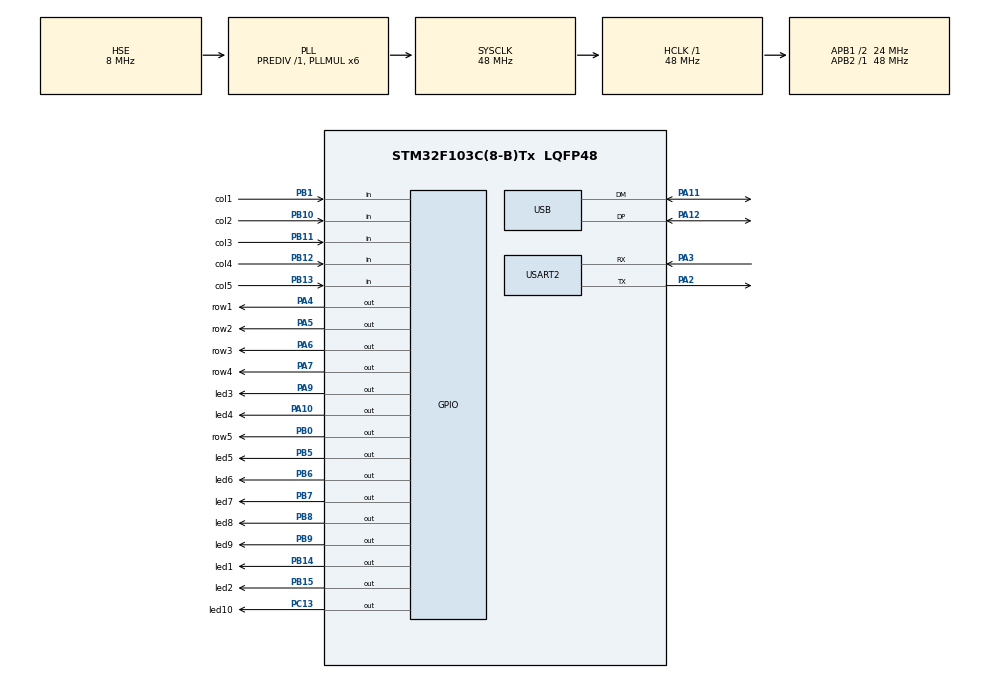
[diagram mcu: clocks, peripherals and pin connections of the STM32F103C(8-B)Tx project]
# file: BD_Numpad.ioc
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Mcu.Family=STM32F1
Mcu.Name=STM32F103C(8-B)Tx
Mcu.Package=LQFP48
NVIC.PriorityGroup=NVIC_PRIORITYGROUP_4
NVIC.USB_LP_CAN1_RX0_IRQn=true\:0\:0\:false\:false\:true\:false\:true\:true
PA10.GPIO_Label=led4
PA10.GPIO_PuPd=GPIO_PULLDOWN
PA10.GPIO_Speed=GPIO_SPEED_FREQ_HIGH
PA10.Signal=GPIO_Output
PA11.Mode=Device
PA11.Signal=USB_DM
PA12.Mode=Device
PA12.Signal=USB_DP
PA13.Mode=Serial_Wire
PA13.Signal=SYS_JTMS-SWDIO
PA14.Mode=Serial_Wire
PA14.Signal=SYS_JTCK-SWCLK
PA2.Mode=Asynchronous
PA2.Signal=USART2_TX
PA3.Mode=Asynchronous
PA3.Signal=USART2_RX
PA4.GPIO_Label=row1
PA4.GPIO_PuPd=GPIO_PULLDOWN
PA4.GPIO_Speed=GPIO_SPEED_FREQ_HIGH
PA4.Signal=GPIO_Output
PA5.GPIO_Label=row2
PA5.GPIO_PuPd=GPIO_PULLDOWN
PA5.GPIO_Speed=GPIO_SPEED_FREQ_HIGH
PA5.Signal=GPIO_Output
PA6.GPIO_Label=row3
PA6.GPIO_PuPd=GPIO_PULLDOWN
PA6.GPIO_Speed=GPIO_SPEED_FREQ_HIGH
PA6.Signal=GPIO_Output
PA7.GPIO_Label=row4
PA7.GPIO_PuPd=GPIO_PULLDOWN
PA7.GPIO_Speed=GPIO_SPEED_FREQ_HIGH
PA7.Signal=GPIO_Output
PA9.GPIO_Label=led3
PA9.GPIO_PuPd=GPIO_PULLDOWN
PA9.GPIO_Speed=GPIO_SPEED_FREQ_HIGH
PA9.Signal=GPIO_Output
PB0.GPIO_Label=row5
PB0.GPIO_PuPd=GPIO_PULLDOWN
PB0.GPIO_Speed=GPIO_SPEED_FREQ_HIGH
PB0.Signal=GPIO_Output
PB1.GPIO_Label=col1
PB1.GPIO_PuPd=GPIO_PULLDOWN
PB1.Signal=GPIO_Input
PB10.GPIO_Label=col2
PB10.GPIO_PuPd=GPIO_PULLDOWN
PB10.Signal=GPIO_Input
PB11.GPIO_Label=col3
PB11.GPIO_PuPd=GPIO_PULLDOWN
PB11.Signal=GPIO_Input
PB12.GPIO_Label=col4
PB12.GPIO_PuPd=GPIO_PULLDOWN
PB12.Signal=GPIO_Input
PB13.GPIO_Label=col5
PB13.GPIO_PuPd=GPIO_PULLDOWN
PB13.Signal=GPIO_Input
PB14.GPIO_Label=led1
PB14.GPIO_PuPd=GPIO_PULLDOWN
PB14.GPIO_Speed=GPIO_SPEED_FREQ_HIGH
PB14.Signal=GPIO_Output
PB15.GPIO_Label=led2
PB15.GPIO_PuPd=GPIO_PULLDOWN
PB15.GPIO_Speed=GPIO_SPEED_FREQ_HIGH
PB15.Signal=GPIO_Output
PB5.GPIO_Label=led5
PB5.GPIO_PuPd=GPIO_PULLDOWN
PB5.GPIO_Speed=GPIO_SPEED_FREQ_HIGH
PB5.Signal=GPIO_Output
PB6.GPIO_Label=led6
PB6.GPIO_PuPd=GPIO_PULLDOWN
PB6.GPIO_Speed=GPIO_SPEED_FREQ_HIGH
PB6.Signal=GPIO_Output
PB7.GPIO_Label=led7
PB7.GPIO_PuPd=GPIO_PULLDOWN
PB7.GPIO_Speed=GPIO_SPEED_FREQ_HIGH
PB7.Signal=GPIO_Output
PB8.GPIO_Label=led8
PB8.GPIO_PuPd=GPIO_PULLDOWN
PB8.GPIO_Speed=GPIO_SPEED_FREQ_HIGH
PB8.Signal=GPIO_Output
PB9.GPIO_Label=led9
PB9.GPIO_PuPd=GPIO_PULLDOWN
PB9.GPIO_Speed=GPIO_SPEED_FREQ_HIGH
PB9.Signal=GPIO_Output
PC13-TAMPER-RTC.GPIO_Label=led10
PC13-TAMPER-RTC.GPIO_PuPd=GPIO_PULLDOWN
PC13-TAMPER-RTC.GPIO_Speed=GPIO_SPEED_FREQ_HIGH
PC13-TAMPER-RTC.Signal=GPIO_Output
PD0-OSC_IN.Mode=HSE-External-Oscillator
PD0-OSC_IN.Signal=RCC_OSC_IN
PD1-OSC_OUT.Mode=HSE-External-Oscillator
PD1-OSC_OUT.Signal=RCC_OSC_OUT
ProjectManager.HeapSize=0x200
ProjectManager.StackSize=0x400
ProjectManager.TargetToolchain=STM32CubeIDE
RCC.AHBFreq_Value=48000000
RCC.APB1CLKDivider=RCC_HCLK_DIV2
RCC.APB1Freq_Value=24000000
RCC.APB1TimFreq_Value=48000000
RCC.APB2Freq_Value=48000000
RCC.APB2TimFreq_Value=48000000
RCC.HCLKFreq_Value=48000000
RCC.PLLMUL=RCC_PLL_MUL6
RCC.SYSCLKFreq_VALUE=48000000
RCC.SYSCLKSource=RCC_SYSCLKSOURCE_PLLCLK
RCC.USBFreq_Value=48000000
USART2.VirtualMode=VM_ASYNC
USB_DEVICE.CLASS_NAME_FS=HID
USB_DEVICE.PRODUCT_STRING_HID_FS=\ BD Numpad
USB_DEVICE.VirtualMode=Hid
USB_DEVICE.VirtualModeFS=Hid_FS
VP_USB_DEVICE_VS_USB_DEVICE_HID_FS.Mode=HID_FS
board=custom

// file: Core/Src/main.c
/* USER CODE BEGIN Header */
/**
  ******************************************************************************
  * @file           : main.c
  * @brief          : Main program body
  ******************************************************************************
  * @attention
  *
  * Copyright (c) 2023 STMicroelectronics.
  * All rights reserved.
  *
  * This software is licensed under terms that can be found in the LICENSE file
  * in the root directory of this software component.
  * If no LICENSE file comes with this software, it is provided AS-IS.
  *
  ******************************************************************************
  */
/* USER CODE END Header */
#include "main.h"
#include "usb_device.h"

/* USER CODE BEGIN Includes */
#include "usbd_hid.h"
#include "HIDKeyFunctions.h"
/* USER CODE END Includes */

UART_HandleTypeDef huart2;

void SystemClock_Config(void);
static void MX_GPIO_Init(void);
static void MX_USART2_UART_Init(void);

/* USER CODE BEGIN 0 */
//extern USBD_HandleTypeDef hUsbDeviceFS;
//https://youtu.be/tj1_hsQ5PR0?t=337   burda kaldin pdf indirdin
/*typedef struct {
	uint8_t MODIFIER;
	uint8_t RESERVED;
	uint8_t KEYCODE1;
	uint8_t KEYCODE2;
	uint8_t KEYCODE3;
	uint8_t KEYCODE4;
	uint8_t KEYCODE5;
	uint8_t KEYCODE6;
} keyboardHID;

keyboardHID keyboardhid = {0,0,0,0,0,0,0,0};
*/
/* USER CODE END 0 */

int main(void)
{

  /* MCU Configuration--------------------------------------------------------*/

  /* Reset of all peripherals, Initializes the Flash interface and the Systick. */
  HAL_Init();

  /* Configure the system clock */
  SystemClock_Config();

  /* Initialize all configured peripherals */
  MX_GPIO_Init();
  MX_USART2_UART_Init();
  MX_USB_DEVICE_Init();
  /* USER CODE BEGIN 2 */
  //turn on all leds.
  HAL_GPIO_WritePin(led1_GPIO_Port, led1_Pin, GPIO_PIN_SET);
  HAL_GPIO_WritePin(led2_GPIO_Port, led2_Pin, GPIO_PIN_SET);
  HAL_GPIO_WritePin(led3_GPIO_Port, led3_Pin, GPIO_PIN_SET);
  HAL_GPIO_WritePin(led4_GPIO_Port, led4_Pin, GPIO_PIN_SET);
  HAL_GPIO_WritePin(led5_GPIO_Port, led5_Pin, GPIO_PIN_SET);
  HAL_GPIO_WritePin(led6_GPIO_Port, le6_Pin, GPIO_PIN_RESET);
  HAL_GPIO_WritePin(led7_GPIO_Port, led7_Pin, GPIO_PIN_RESET);
  HAL_GPIO_WritePin(led8_GPIO_Port, led8_Pin, GPIO_PIN_RESET);
  HAL_GPIO_WritePin(led9_GPIO_Port, led9_Pin, GPIO_PIN_RESET);
  HAL_GPIO_WritePin(led10_GPIO_Port, led10_Pin, GPIO_PIN_RESET);

  /* USER CODE END 2 */

  /* Infinite loop */
  while (1)
  {

    /* USER CODE BEGIN 3 */
	  /*
	  keyboardhid.KEYCODE1 = 0x1e; //send '1'
	  USBD_HID_SendReport(&hUsbDeviceFS, &keyboardhid, sizeof(keyboardhid));

	  HAL_Delay(50);

	  keyboardhid.KEYCODE1 = 0x00; //release key
	  USBD_HID_SendReport(&hUsbDeviceFS, &keyboardhid, sizeof(keyboardhid));
	   */

	  //HAL_Delay(10000);
	  //https://youtu.be/tj1_hsQ5PR0?t=537

	  readAllPins();
	  HAL_Delay(10);

  }
  /* USER CODE END 3 */
}

void SystemClock_Config(void)
{
  RCC_OscInitTypeDef RCC_OscInitStruct = {0};
  RCC_ClkInitTypeDef RCC_ClkInitStruct = {0};
  RCC_PeriphCLKInitTypeDef PeriphClkInit = {0};

  /** Initializes the RCC Oscillators according to the specified parameters
  * in the RCC_OscInitTypeDef structure.
  */
  RCC_OscInitStruct.OscillatorType = RCC_OSCILLATORTYPE_HSE;
  RCC_OscInitStruct.HSEState = RCC_HSE_ON;
  RCC_OscInitStruct.HSEPredivValue = RCC_HSE_PREDIV_DIV1;
  RCC_OscInitStruct.HSIState = RCC_HSI_ON;
  RCC_OscInitStruct.PLL.PLLState = RCC_PLL_ON;
  RCC_OscInitStruct.PLL.PLLSource = RCC_PLLSOURCE_HSE;
  RCC_OscInitStruct.PLL.PLLMUL = RCC_PLL_MUL6;
  if (HAL_RCC_OscConfig(&RCC_OscInitStruct) != HAL_OK)
  {
    Error_Handler();
  }

  /** Initializes the CPU, AHB and APB buses clocks
  */
  RCC_ClkInitStruct.ClockType = RCC_CLOCKTYPE_HCLK|RCC_CLOCKTYPE_SYSCLK
                              |RCC_CLOCKTYPE_PCLK1|RCC_CLOCKTYPE_PCLK2;
  RCC_ClkInitStruct.SYSCLKSource = RCC_SYSCLKSOURCE_PLLCLK;
  RCC_ClkInitStruct.AHBCLKDivider = RCC_SYSCLK_DIV1;
  RCC_ClkInitStruct.APB1CLKDivider = RCC_HCLK_DIV2;
  RCC_ClkInitStruct.APB2CLKDivider = RCC_HCLK_DIV1;

  if (HAL_RCC_ClockConfig(&RCC_ClkInitStruct, FLASH_LATENCY_1) != HAL_OK)
  {
    Error_Handler();
  }
  PeriphClkInit.PeriphClockSelection = RCC_PERIPHCLK_USB;
  PeriphClkInit.UsbClockSelection = RCC_USBCLKSOURCE_PLL;
  if (HAL_RCCEx_PeriphCLKConfig(&PeriphClkInit) != HAL_OK)
  {
    Error_Handler();
  }
}

static void MX_USART2_UART_Init(void)
{

  huart2.Instance = USART2;
  huart2.Init.BaudRate = 115200;
  huart2.Init.WordLength = UART_WORDLENGTH_8B;
  huart2.Init.StopBits = UART_STOPBITS_1;
  huart2.Init.Parity = UART_PARITY_NONE;
  huart2.Init.Mode = UART_MODE_TX_RX;
  huart2.Init.HwFlowCtl = UART_HWCONTROL_NONE;
  huart2.Init.OverSampling = UART_OVERSAMPLING_16;
  if (HAL_UART_Init(&huart2) != HAL_OK)
  {
    Error_Handler();
  }

}

static void MX_GPIO_Init(void)
{
  GPIO_InitTypeDef GPIO_InitStruct = {0};

  /* GPIO Ports Clock Enable */
  __HAL_RCC_GPIOC_CLK_ENABLE();
  __HAL_RCC_GPIOD_CLK_ENABLE();
  __HAL_RCC_GPIOA_CLK_ENABLE();
  __HAL_RCC_GPIOB_CLK_ENABLE();

  /*Configure GPIO pin Output Level */
  HAL_GPIO_WritePin(led10_GPIO_Port, led10_Pin, GPIO_PIN_RESET);

  /*Configure GPIO pin Output Level */
  HAL_GPIO_WritePin(GPIOA, row1_Pin|row2_Pin|row3_Pin|row4_Pin
                          |led3_Pin|led4_Pin, GPIO_PIN_RESET);

  /*Configure GPIO pin Output Level */
  HAL_GPIO_WritePin(GPIOB, row5_Pin|led1_Pin|led2_Pin|led5_Pin
                          |led6_Pin|led7_Pin|led8_Pin|led9_Pin, GPIO_PIN_RESET);

  /*Configure GPIO pin : led10_Pin */
  GPIO_InitStruct.Pin = led10_Pin;
  GPIO_InitStruct.Mode = GPIO_MODE_OUTPUT_PP;
  GPIO_InitStruct.Pull = GPIO_PULLDOWN;
  GPIO_InitStruct.Speed = GPIO_SPEED_FREQ_HIGH;
  HAL_GPIO_Init(led10_GPIO_Port, &GPIO_InitStruct);

  /*Configure GPIO pins : row1_Pin row2_Pin row3_Pin row4_Pin
                           led3_Pin led4_Pin */
  GPIO_InitStruct.Pin = row1_Pin|row2_Pin|row3_Pin|row4_Pin
                          |led3_Pin|led4_Pin;
  GPIO_InitStruct.Mode = GPIO_MODE_OUTPUT_PP;
  GPIO_InitStruct.Pull = GPIO_PULLDOWN;
  GPIO_InitStruct.Speed = GPIO_SPEED_FREQ_HIGH;
  HAL_GPIO_Init(GPIOA, &GPIO_InitStruct);

  /*Configure GPIO pins : row5_Pin led1_Pin led2_Pin led5_Pin
                           led6_Pin led7_Pin led8_Pin led9_Pin */
  GPIO_InitStruct.Pin = row5_Pin|led1_Pin|led2_Pin|led5_Pin
                          |led6_Pin|led7_Pin|led8_Pin|led9_Pin;
  GPIO_InitStruct.Mode = GPIO_MODE_OUTPUT_PP;
  GPIO_InitStruct.Pull = GPIO_PULLDOWN;
  GPIO_InitStruct.Speed = GPIO_SPEED_FREQ_HIGH;
  HAL_GPIO_Init(GPIOB, &GPIO_InitStruct);

  /*Configure GPIO pins : col1_Pin col2_Pin col3_Pin col4_Pin
                           col5_Pin */
  GPIO_InitStruct.Pin = col1_Pin|col2_Pin|col3_Pin|col4_Pin
                          |col5_Pin;
  GPIO_InitStruct.Mode = GPIO_MODE_INPUT;
  GPIO_InitStruct.Pull = GPIO_PULLDOWN;
  HAL_GPIO_Init(GPIOB, &GPIO_InitStruct);

}

void Error_Handler(void)
{
  __disable_irq();
  while (1)
  {
  }
}
